# MKV30F12810 register map
Vendor: Freescale Semiconductor, Inc.; File version: 1.6
MKV30F12810 Freescale Microcontroller
CPU: CM4 r0p1, little endian, no MPU, no FPU, 0x4 interrupt priority bits, 0x0 interrupts
Registers are 32-bit, read-write, reset 0x0 unless marked. A register's access mark holds for its fields unless they carry their own. Offsets are from the block's base; lines under a group give offsets from that group; [hi:lo] are bit positions; {n}, {i} and the like mark numbered series; 'fields as' and 'values as' point back to an identical list; <NAME> marks a mode.

## Memory map
0x00000400 FTFA_FlashConfig size 0xE — Flash configuration field
0x40008000 DMA size 0x1080 — Enhanced direct memory access controller
0x4001F000 FMC size 0x300 — Flash Memory Controller
0x40020000 FTFA size 0x2C — Flash Memory Interface
0x40021000 DMAMUX size 0x4 — DMA channel multiplexor
0x40027000 ADC1 size 0x70 — Analog-to-Digital Converter
0x4002C000 SPI0 size 0x8C — Serial Peripheral Interface
0x40032000 CRC size 0xC — Cyclic Redundancy Check
0x40036000 PDB0 size 0x19C — Programmable Delay Block
0x40037000 PIT size 0x140 — Periodic Interrupt Timer
0x40038000 FTM0 size 0x9C — FlexTimer Module
0x40039000 FTM1 size 0x9C — FlexTimer Module
0x4003A000 FTM2 size 0x9C — FlexTimer Module
0x4003B000 ADC0 size 0x70 — Analog-to-Digital Converter
0x4003F000 DAC0 size 0x24 — 12-Bit Digital-to-Analog Converter
0x40040000 LPTMR0 size 0x10 — Low Power Timer
0x40047000 SIM size 0x1064 — System Integration Module
0x40049000 PORTA size 0xA4 — Pin Control and Interrupts
0x4004A000 PORTB size 0xA4 — Pin Control and Interrupts
0x4004B000 PORTC size 0xA4 — Pin Control and Interrupts
0x4004C000 PORTD size 0xCC — Pin Control and Interrupts
0x4004D000 PORTE size 0xA4 — Pin Control and Interrupts
0x40052000 WDOG size 0x18 — Generation 2008 Watchdog Timer
0x40061000 EWM size 0x6 — External Watchdog Monitor
0x40064000 MCG size 0xE — Multipurpose Clock Generator module
0x40065000 OSC size 0x3 — Oscillator
0x40066000 I2C0 size 0xC — Inter-Integrated Circuit
0x4006A000 UART0 size 0x17 — Serial Communication Interface
0x4006B000 UART1 size 0x17 — Serial Communication Interface
0x40073000 CMP0 size 0x6 — High-Speed Comparator (CMP), Voltage Reference (VREF) Digital-to-Analog Converter (DAC), and Analog Mux (ANMUX)
0x40073008 CMP1 size 0x6 — High-Speed Comparator (CMP), Voltage Reference (VREF) Digital-to-Analog Converter (DAC), and Analog Mux (ANMUX)
0x40074000 VREF size 0x2 — Voltage Reference
0x4007C000 LLWU size 0xA — Low leakage wakeup unit
0x4007D000 PMC size 0x3 — Power Management Controller
0x4007E000 SMC size 0x4 — System Mode Controller
0x4007F000 RCM size 0xA — Reset Control Module
0x400FF000 PTA size 0x18 — General Purpose Input/Output
0x400FF040 PTB size 0x18 — General Purpose Input/Output
0x400FF080 PTC size 0x18 — General Purpose Input/Output
0x400FF0C0 PTD size 0x18 — General Purpose Input/Output
0x400FF100 PTE size 0x18 — General Purpose Input/Output
0xE0080000 MCM blocks up to offset 0x44 — Core Platform Miscellaneous Control Module

## Interrupts
0 DMA0 (DMA)
1 DMA1 (DMA)
2 DMA2 (DMA)
3 DMA3 (DMA)
16 DMA_Error (DMA)
17 MCM
18 FTF (FTFA)
19 Read_Collision (FTFA)
20 LVD_LVW (PMC)
21 LLWU
22 WDOG_EWM (WDOG, EWM)
24 I2C0
26 SPI0
31 UART0_RX_TX (UART0)
32 UART0_ERR (UART0)
33 UART1_RX_TX (UART1)
34 UART1_ERR (UART1)
39 ADC0
40 CMP0
41 CMP1
42 FTM0
43 FTM1
44 FTM2
48 PIT0 (PIT)
49 PIT1 (PIT)
50 PIT2 (PIT)
51 PIT3 (PIT)
52 PDB0
56 DAC0
58 LPTMR0
59 PORTA (PORTA, PTA)
60 PORTB (PORTB, PTB)
61 PORTC (PORTC, PTC)
62 PORTD (PORTD, PTD)
63 PORTE (PORTE, PTE)
73 ADC1

## FTFA_FlashConfig — Flash configuration field
Base 0x00000400; register names take the prefix NV_
0x00 BACKKEY3 8-bit ro reset 0xFF — Backdoor Comparison Key 3.
  [7:0] KEY — Backdoor Comparison Key.
0x01 BACKKEY2 8-bit ro reset 0xFF — Backdoor Comparison Key 2.
  [7:0] KEY — Backdoor Comparison Key.
0x02 BACKKEY1 8-bit ro reset 0xFF — Backdoor Comparison Key 1.
  [7:0] KEY — Backdoor Comparison Key.
0x03 BACKKEY0 8-bit ro reset 0xFF — Backdoor Comparison Key 0.
  [7:0] KEY — Backdoor Comparison Key.
0x04 BACKKEY7 8-bit ro reset 0xFF — Backdoor Comparison Key 7.
  [7:0] KEY — Backdoor Comparison Key.
0x05 BACKKEY6 8-bit ro reset 0xFF — Backdoor Comparison Key 6.
  [7:0] KEY — Backdoor Comparison Key.
0x06 BACKKEY5 8-bit ro reset 0xFF — Backdoor Comparison Key 5.
  [7:0] KEY — Backdoor Comparison Key.
0x07 BACKKEY4 8-bit ro reset 0xFF — Backdoor Comparison Key 4.
  [7:0] KEY — Backdoor Comparison Key.
0x08 FPROT3 8-bit ro reset 0xFF — Non-volatile P-Flash Protection 1 - Low Register
  [7:0] PROT — P-Flash Region Protect
0x09 FPROT2 8-bit ro reset 0xFF — Non-volatile P-Flash Protection 1 - High Register
  [7:0] PROT — P-Flash Region Protect
0x0A FPROT1 8-bit ro reset 0xFF — Non-volatile P-Flash Protection 0 - Low Register
  [7:0] PROT — P-Flash Region Protect
0x0B FPROT0 8-bit ro reset 0xFF — Non-volatile P-Flash Protection 0 - High Register
  [7:0] PROT — P-Flash Region Protect
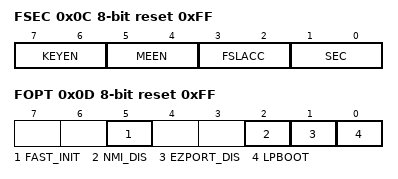
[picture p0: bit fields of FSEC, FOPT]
0x0C FSEC 8-bit ro reset 0xFF — Non-volatile Flash Security Register
  [7:6] KEYEN — Backdoor Key Security Enable
    2=Backdoor key access enabled; 3=Backdoor key access disabled
  [5:4] MEEN
    2=Mass erase is disabled; 3=Mass erase is enabled
  [3:2] FSLACC — Freescale Failure Analysis Access Code
    2=Freescale factory access denied; 3=Freescale factory access granted
  [1:0] SEC — Flash Security
    2=MCU security status is unsecure; 3=MCU security status is secure
0x0D FOPT 8-bit ro reset 0xFF — Non-volatile Flash Option Register
  [5] FAST_INIT
    0=Slower initialization; 1=Fast Initialization
  [2] NMI_DIS
    0=NMI interrupts are always blocked; 1=NMI_b pin/interrupts reset default to enabled
  [1] EZPORT_DIS
    0=EzPort operation is disabled; 1=EzPort operation is enabled
  [0] LPBOOT
    0=Low-power boot; 1=Normal boot
